AUTOSAR XML (schema 4-3-0)
package /ComponentTypes
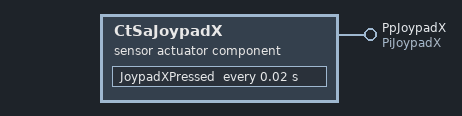
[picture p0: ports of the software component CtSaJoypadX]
  sensor actuator sw component type CtSaJoypadX
    provide port PpJoypadX: nonqueued-sender-com-spec{data-element=DeJoypadX, init-value=0}, provided-interface=PiJoypadX
    behavior CtSaJoypadX_InternalBehavior
      timing event TMT_JoypadXPressed: start-on-event=JoypadXPressed, period=0.02
      runnable JoypadXPressed
        data-send-points:
          access SEND_PpJoypadX_DeJoypadX: accessed-variable=PpJoypadX.DeJoypadX
  swc implementation CtSaJoypadX_Implementation: behavior=CtSaJoypadX_InternalBehavior
